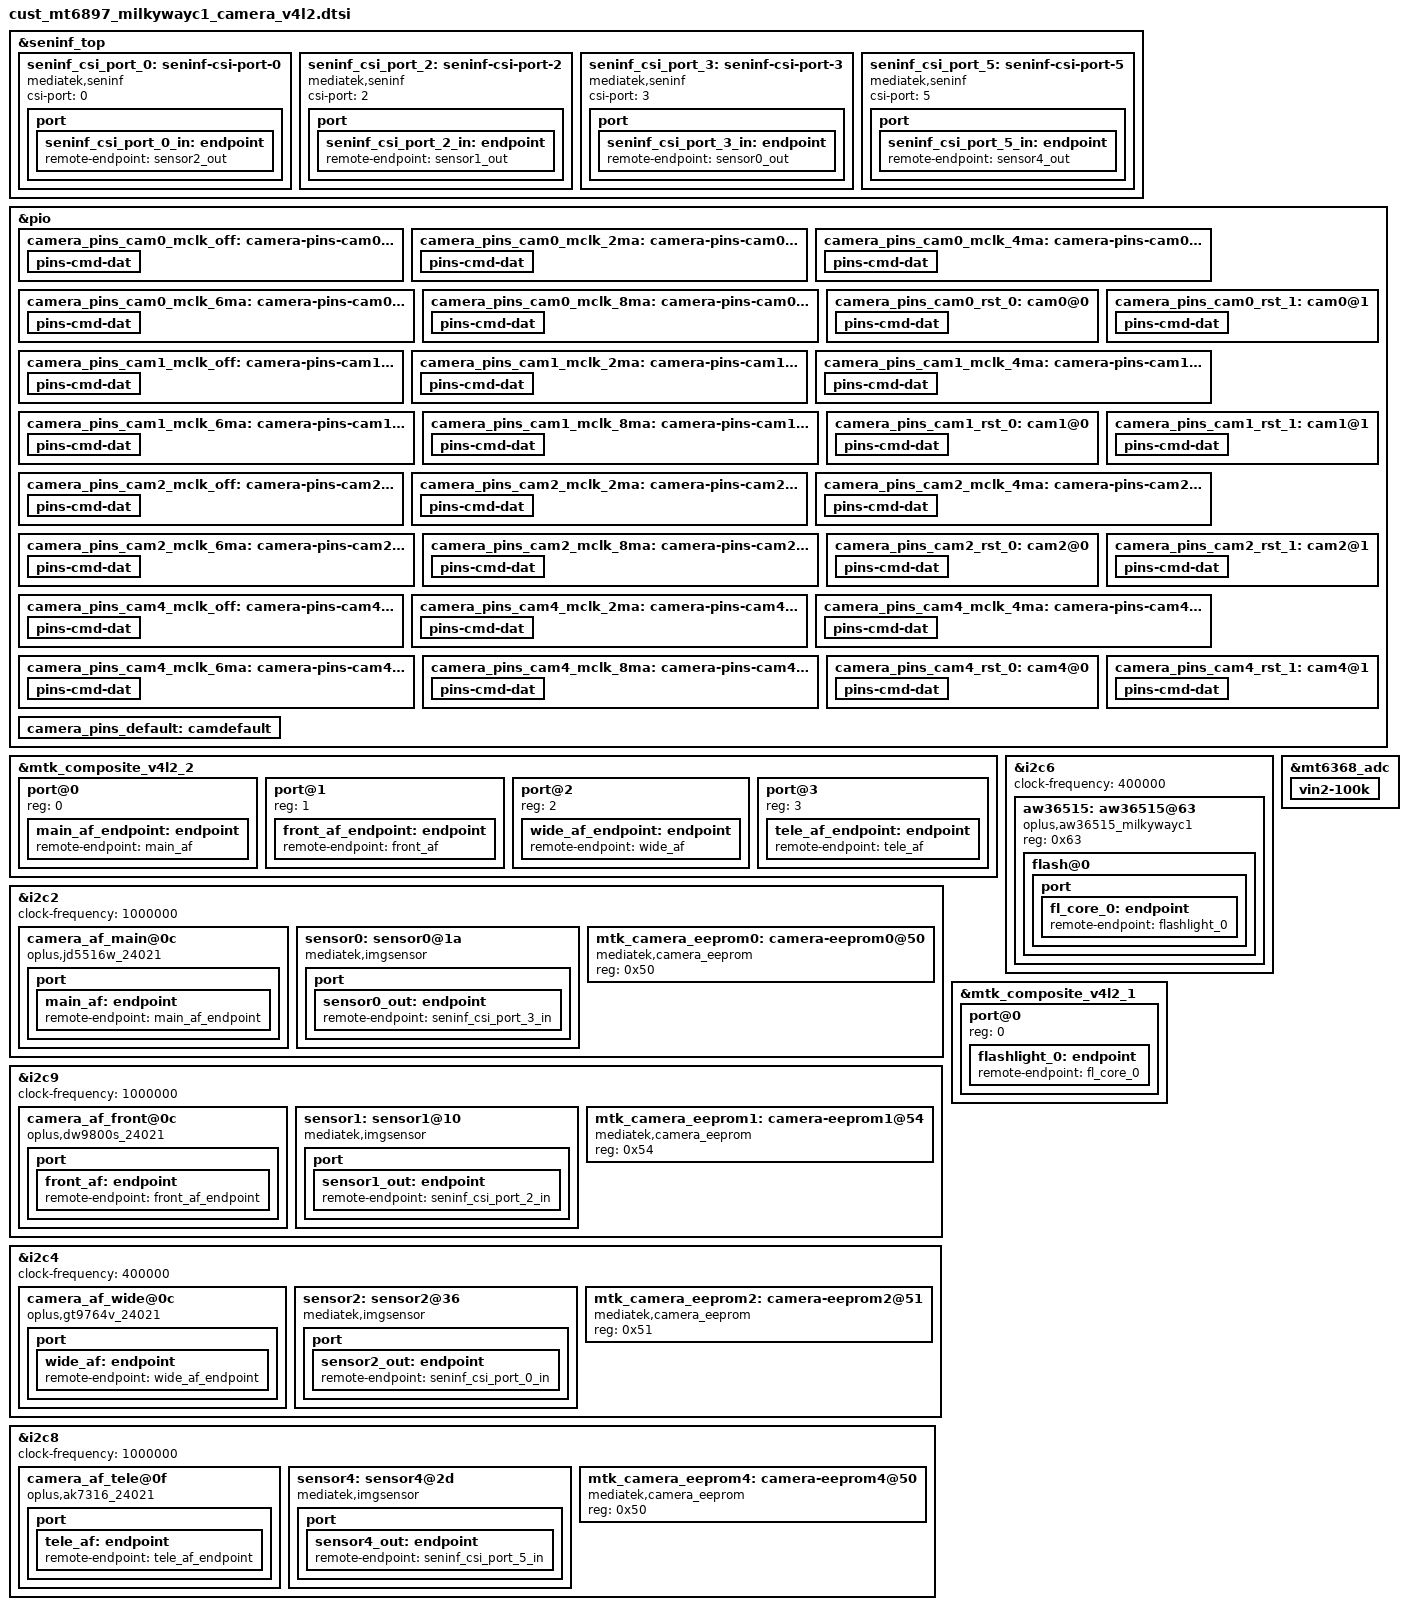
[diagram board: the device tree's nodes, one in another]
// SPDX-License-Identifier: GPL-2.0
/* Copyright (c) 2020 MediaTek Inc. */
#include <dt-bindings/clock/mt6897-clk.h>
#include "mediatek/milkywayc1_regulator_wl28681c.dtsi"
#include "../../../../../../vendor/oplus/kernel/camera/imgsensor/inc/oplus_kd_imgsensor.h"

&seninf_top {
		seninf_csi_port_0: seninf-csi-port-0 {
			compatible = "mediatek,seninf";
			csi-port = "0";

			port {
				seninf_csi_port_0_in: endpoint {
					remote-endpoint = <&sensor2_out>;
				};
			};
		};

		seninf_csi_port_2: seninf-csi-port-2 {
			compatible = "mediatek,seninf";
			csi-port = "2";

			port {
				seninf_csi_port_2_in: endpoint {
					remote-endpoint = <&sensor1_out>;
				};
			};
		};

		seninf_csi_port_3: seninf-csi-port-3 {
			compatible = "mediatek,seninf";
			csi-port = "3";

			port {
				seninf_csi_port_3_in: endpoint {
					remote-endpoint = <&sensor0_out>;
				};
			};
		};

		seninf_csi_port_5: seninf-csi-port-5 {
			compatible = "mediatek,seninf";
			csi-port = "5";

			port {
				seninf_csi_port_5_in: endpoint {
					remote-endpoint = <&sensor4_out>;
				};
			};
		};
};

/* CAMERA GPIO standardization */
&pio {
	camera_pins_cam0_mclk_off: camera-pins-cam0-mclk-off {
		pins-cmd-dat {
			pinmux = <PINMUX_GPIO123__FUNC_GPIO123>;
			drive-strength = <1>;
		};
	};
	camera_pins_cam0_mclk_2ma: camera-pins-cam0-mclk-2ma {
		pins-cmd-dat {
			pinmux = <PINMUX_GPIO123__FUNC_CMMCLK0>;
			drive-strength = <0>;
		};
	};
	camera_pins_cam0_mclk_4ma: camera-pins-cam0-mclk-4ma {
		pins-cmd-dat {
			pinmux = <PINMUX_GPIO123__FUNC_CMMCLK0>;
			drive-strength = <1>;
		};
	};
	camera_pins_cam0_mclk_6ma: camera-pins-cam0-mclk-6ma {
		pins-cmd-dat {
			pinmux = <PINMUX_GPIO123__FUNC_CMMCLK0>;
			drive-strength = <2>;
		};
	};
	camera_pins_cam0_mclk_8ma: camera-pins-cam0-mclk-8ma {
		pins-cmd-dat {
			pinmux = <PINMUX_GPIO123__FUNC_CMMCLK0>;
			drive-strength = <3>;
		};
	};
	camera_pins_cam0_rst_0: cam0@0 {
		pins-cmd-dat {
			pinmux = <PINMUX_GPIO115__FUNC_GPIO115>;
			slew-rate = <1>;
			output-low;
		};
	};
	camera_pins_cam0_rst_1: cam0@1 {
		pins-cmd-dat {
			pinmux = <PINMUX_GPIO115__FUNC_GPIO115>;
			slew-rate = <1>;
			output-high;
		};
	};

	camera_pins_cam1_mclk_off: camera-pins-cam1-mclk-off {
		pins-cmd-dat {
			pinmux = <PINMUX_GPIO126__FUNC_GPIO126>;
			drive-strength = <1>;
		};
	};
	camera_pins_cam1_mclk_2ma: camera-pins-cam1-mclk-2ma {
		pins-cmd-dat {
			pinmux = <PINMUX_GPIO126__FUNC_CMMCLK3>;
			drive-strength = <0>;
		};
	};
	camera_pins_cam1_mclk_4ma: camera-pins-cam1-mclk-4ma {
		pins-cmd-dat {
			pinmux = <PINMUX_GPIO126__FUNC_CMMCLK3>;
			drive-strength = <1>;
		};
	};
	camera_pins_cam1_mclk_6ma: camera-pins-cam1-mclk-6ma {
		pins-cmd-dat {
			pinmux = <PINMUX_GPIO126__FUNC_CMMCLK3>;
			drive-strength = <2>;
		};
	};
	camera_pins_cam1_mclk_8ma: camera-pins-cam1-mclk-8ma {
		pins-cmd-dat {
			pinmux = <PINMUX_GPIO126__FUNC_CMMCLK3>;
			drive-strength = <3>;
		};
	};
	camera_pins_cam1_rst_0: cam1@0 {
		pins-cmd-dat {
			pinmux = <PINMUX_GPIO118__FUNC_GPIO118>;
			slew-rate = <1>;
			output-low;
		};
	};
	camera_pins_cam1_rst_1: cam1@1 {
		pins-cmd-dat {
			pinmux = <PINMUX_GPIO118__FUNC_GPIO118>;
			slew-rate = <1>;
			output-high;
		};
	};

	camera_pins_cam2_mclk_off: camera-pins-cam2-mclk-off {
		pins-cmd-dat {
			pinmux = <PINMUX_GPIO124__FUNC_GPIO124>;
			drive-strength = <1>;
		};
	};
	camera_pins_cam2_mclk_2ma: camera-pins-cam2-mclk-2ma {
		pins-cmd-dat {
			pinmux = <PINMUX_GPIO124__FUNC_CMMCLK1>;
			drive-strength = <0>;
		};
	};
	camera_pins_cam2_mclk_4ma: camera-pins-cam2-mclk-4ma {
		pins-cmd-dat {
			pinmux = <PINMUX_GPIO124__FUNC_CMMCLK1>;
			drive-strength = <1>;
		};
	};
	camera_pins_cam2_mclk_6ma: camera-pins-cam2-mclk-6ma {
		pins-cmd-dat {
			pinmux = <PINMUX_GPIO124__FUNC_CMMCLK1>;
			drive-strength = <2>;
		};
	};
	camera_pins_cam2_mclk_8ma: camera-pins-cam2-mclk-8ma {
		pins-cmd-dat {
			pinmux = <PINMUX_GPIO124__FUNC_CMMCLK1>;
			drive-strength = <3>;
		};
	};
	camera_pins_cam2_rst_0: cam2@0 {
		pins-cmd-dat {
			pinmux = <PINMUX_GPIO116__FUNC_GPIO116>;
			slew-rate = <1>;
			output-low;
		};
	};
	camera_pins_cam2_rst_1: cam2@1 {
		pins-cmd-dat {
			pinmux = <PINMUX_GPIO116__FUNC_GPIO116>;
			slew-rate = <1>;
			output-high;
		};
	};

	camera_pins_cam4_mclk_off: camera-pins-cam4-mclk-off {
		pins-cmd-dat {
			pinmux = <PINMUX_GPIO125__FUNC_GPIO125>;
			drive-strength = <1>;
		};
	};
	camera_pins_cam4_mclk_2ma: camera-pins-cam4-mclk-2ma {
		pins-cmd-dat {
			pinmux = <PINMUX_GPIO125__FUNC_CMMCLK2>;
			drive-strength = <0>;
		};
	};
	camera_pins_cam4_mclk_4ma: camera-pins-cam4-mclk-4ma {
		pins-cmd-dat {
			pinmux = <PINMUX_GPIO125__FUNC_CMMCLK2>;
			drive-strength = <1>;
		};
	};
	camera_pins_cam4_mclk_6ma: camera-pins-cam4-mclk-6ma {
		pins-cmd-dat {
			pinmux = <PINMUX_GPIO125__FUNC_CMMCLK2>;
			drive-strength = <2>;
		};
	};
	camera_pins_cam4_mclk_8ma: camera-pins-cam4-mclk-8ma {
		pins-cmd-dat {
			pinmux = <PINMUX_GPIO125__FUNC_CMMCLK2>;
			drive-strength = <3>;
		};
	};
	camera_pins_cam4_rst_0: cam4@0 {
		pins-cmd-dat {
			pinmux = <PINMUX_GPIO117__FUNC_GPIO117>;
			slew-rate = <1>;
			output-low;
		};
	};
	camera_pins_cam4_rst_1: cam4@1 {
		pins-cmd-dat {
			pinmux = <PINMUX_GPIO117__FUNC_GPIO117>;
			slew-rate = <1>;
			output-high;
		};
	};
	camera_pins_default: camdefault {
	};
};
/* CAMERA GPIO end */

&mtk_composite_v4l2_2 {
	#address-cells = <1>;
	#size-cells = <0>;

	port@0 {
		reg = <0>;
		main_af_endpoint: endpoint {
			remote-endpoint = <&main_af>;
		};
	};
	port@1 {
		reg = <1>;
		front_af_endpoint: endpoint {
			remote-endpoint = <&front_af>;
		};
	};

	port@2 {
		reg = <2>;
		wide_af_endpoint: endpoint {
			remote-endpoint = <&wide_af>;
		};
	};

	port@3 {
		reg = <3>;
		tele_af_endpoint: endpoint {
			remote-endpoint = <&tele_af>;
		};
	};
};

&i2c2 {
	status = "okay";
	clock-frequency = <1000000>;

	camera_af_main@0c {
		compatible = "oplus,jd5516w_24021";
		reg = <0x0c>;
		vin-supply = <&wl28681c1_ldo4a>;
		port {
			main_af: endpoint {
				remote-endpoint = <&main_af_endpoint>;
			};
		};
	};

	sensor0: sensor0@1a {
		compatible = "mediatek,imgsensor";
		sensor-names = SENSOR_DRVNAME_MILKYWAYC1MAIN_MIPI_RAW;
		sensor-ids = <MILKYWAYC1MAIN_SENSOR_ID>;

		reg = <0x1a>;

		#thermal-sensor-cells = <0>;

		pinctrl-names = "mclk_off",
				"mclk_2mA",
				"mclk_4mA",
				"mclk_6mA",
				"mclk_8mA",
				"rst_low",
				"rst_high";
		pinctrl-0 = <&camera_pins_cam0_mclk_off>;
		pinctrl-1 = <&camera_pins_cam0_mclk_2ma>;
		pinctrl-2 = <&camera_pins_cam0_mclk_4ma>;
		pinctrl-3 = <&camera_pins_cam0_mclk_6ma>;
		pinctrl-4 = <&camera_pins_cam0_mclk_8ma>;
		pinctrl-5 = <&camera_pins_cam0_rst_0>;
		pinctrl-6 = <&camera_pins_cam0_rst_1>;

		avdd-supply = <&wl28681c1_ldo3a>;
		avdd1-supply = <&wl28681c1_ldo5a>;
		dvdd-supply = <&wl28681c1_ldo1a>;
		dovdd-supply = <&mt6368_vfp>;
		afvdd-supply = <&wl28681c1_ldo4a>;

		clocks = <&topckgen_clk CLK_TOP_UNIVPLL_192M_D32>,
			<&topckgen_clk CLK_TOP_UNIVPLL_192M_D16>,
			<&topckgen_clk CLK_TOP_F26M_CK_D2>,
			<&topckgen_clk CLK_TOP_UNIVPLL_192M_D10>,
			<&topckgen_clk CLK_TOP_UNIVPLL_192M_D8>,
			<&topckgen_clk CLK_TOP_UNIVPLL_D6_D16>,
			<&topckgen_clk CLK_TOP_UNIVPLL_D6_D8>,
			<&vlp_cksys_clk CLK_VLP_CK_CAMTG_SEL>;  //mclk0
		clock-names = "6", "12", "13", "19.2", "24", "26", "52", "mclk";

		status = "okay";
		port {
			sensor0_out: endpoint {
				remote-endpoint = <&seninf_csi_port_3_in>;
			};
		};
	};

	mtk_camera_eeprom0:camera-eeprom0@50 {
		compatible = "mediatek,camera_eeprom";
		reg = <0x50>;
		status = "okay";
	};
};

&i2c9 {
	status = "okay";
	clock-frequency = <1000000>;

	camera_af_front@0c {
		compatible = "oplus,dw9800s_24021";
		reg = <0x0c>;
		vin-supply = <&wl28681c1_ldo4a>;
		port {
			front_af: endpoint {
				remote-endpoint = <&front_af_endpoint>;
			};
		};
	};

	sensor1: sensor1@10 {
		compatible = "mediatek,imgsensor";
		sensor-names = SENSOR_DRVNAME_MILKYWAYC1FRONT_MIPI_RAW;
		sensor-ids = <MILKYWAYC1FRONT_SENSOR_ID>;

		reg = <0x10>;
		#reindex-to = <0>;
		#cust-aov-csi-clk = <312>;
		#thermal-sensor-cells = <0>;

		pinctrl-names = "mclk_off",
				"mclk_2mA",
				"mclk_4mA",
				"mclk_6mA",
				"mclk_8mA",
				"rst_low",
				"rst_high";

		pinctrl-0 = <&camera_pins_cam1_mclk_off>;
		pinctrl-1 = <&camera_pins_cam1_mclk_2ma>;
		pinctrl-2 = <&camera_pins_cam1_mclk_4ma>;
		pinctrl-3 = <&camera_pins_cam1_mclk_6ma>;
		pinctrl-4 = <&camera_pins_cam1_mclk_8ma>;
		pinctrl-5 = <&camera_pins_cam1_rst_0>;
		pinctrl-6 = <&camera_pins_cam1_rst_1>;

		avdd-supply = <&wl28681c1_ldo6a>;
		dvdd-supply = <&mt6319_7_vbuck4>;
		dvdd1-supply = <&wl28681c1_ldo2a>;
		dvdd-mode = <0x01>;   // REGULATOR_MODE_FAST
		dovdd-supply = <&mt6368_vfp>;
		afvdd-supply = <&wl28681c1_ldo4a>;

		clocks = <&topckgen_clk CLK_TOP_UNIVPLL_192M_D32>,
			<&topckgen_clk CLK_TOP_UNIVPLL_192M_D16>,
			<&topckgen_clk CLK_TOP_F26M_CK_D2>,
			<&topckgen_clk CLK_TOP_UNIVPLL_192M_D10>,
			<&topckgen_clk CLK_TOP_UNIVPLL_192M_D8>,
			<&topckgen_clk CLK_TOP_UNIVPLL_D6_D16>,
			<&topckgen_clk CLK_TOP_UNIVPLL_D6_D8>,
			<&topckgen_clk CLK_TOP_CAMTG4_SEL>;   //mclk3
		clock-names = "6", "12", "13", "19.2", "24", "26", "52", "mclk";

		status = "okay";
		port {
			sensor1_out: endpoint {
				remote-endpoint = <&seninf_csi_port_2_in>;
			};
		};
	};

    mtk_camera_eeprom1:camera-eeprom1@54 {
		compatible = "mediatek,camera_eeprom";
		reg = <0x54>;
		status = "okay";
	};
};

&i2c4 {
	status = "okay";
	clock-frequency = <400000>;

	camera_af_wide@0c {
		compatible = "oplus,gt9764v_24021";
		reg = <0x0c>;
		vin-supply = <&wl28681c1_ldo4a>;
		port {
			wide_af: endpoint {
				remote-endpoint = <&wide_af_endpoint>;
			};
		};
	};

   sensor2: sensor2@36 {
		compatible = "mediatek,imgsensor";
		sensor-names = SENSOR_DRVNAME_MILKYWAYC1WIDE_MIPI_RAW;
		sensor-ids = <MILKYWAYC1WIDE_SENSOR_ID>;

		reg = <0x36>;
		#reindex-to = <0>;
		#cust-aov-csi-clk = <312>;
		#thermal-sensor-cells = <0>;

		pinctrl-names = "mclk_off",
				"mclk_2mA",
				"mclk_4mA",
				"mclk_6mA",
				"mclk_8mA",
				"rst_low",
				"rst_high";

		pinctrl-0 = <&camera_pins_cam2_mclk_off>;
		pinctrl-1 = <&camera_pins_cam2_mclk_2ma>;
		pinctrl-2 = <&camera_pins_cam2_mclk_4ma>;
		pinctrl-3 = <&camera_pins_cam2_mclk_6ma>;
		pinctrl-4 = <&camera_pins_cam2_mclk_8ma>;
		pinctrl-5 = <&camera_pins_cam2_rst_0>;
		pinctrl-6 = <&camera_pins_cam2_rst_1>;

		avdd-supply = <&wl28681c1_ldo3a>;
		dvdd-supply = <&mt6368_vrf13_aif>;
		dovdd-supply = <&mt6368_vfp>;
		afvdd-supply = <&wl28681c1_ldo4a>;

		clocks = <&topckgen_clk CLK_TOP_UNIVPLL_192M_D32>,
			<&topckgen_clk CLK_TOP_UNIVPLL_192M_D16>,
			<&topckgen_clk CLK_TOP_F26M_CK_D2>,
			<&topckgen_clk CLK_TOP_UNIVPLL_192M_D10>,
			<&topckgen_clk CLK_TOP_UNIVPLL_192M_D8>,
			<&topckgen_clk CLK_TOP_UNIVPLL_D6_D16>,
			<&topckgen_clk CLK_TOP_UNIVPLL_D6_D8>,
			<&topckgen_clk CLK_TOP_CAMTG2_SEL>;  //mclk1
		clock-names = "6", "12", "13", "19.2", "24", "26", "52", "mclk";

		status = "okay";
		port {
			sensor2_out: endpoint {
				remote-endpoint = <&seninf_csi_port_0_in>;
			};
		};
	};

	mtk_camera_eeprom2:camera-eeprom2@51 {
		compatible = "mediatek,camera_eeprom";
		reg = <0x51>;
		status = "okay";
	};
};

&i2c8 {
	status = "okay";
	clock-frequency = <1000000>;

	camera_af_tele@0f {
		compatible = "oplus,ak7316_24021";
		reg = <0x0f>;
		vin-supply = <&wl28681c1_ldo7a>;
		port {
			tele_af: endpoint {
				remote-endpoint = <&tele_af_endpoint>;
			};
		};
	};

	sensor4: sensor4@2d {
		compatible = "mediatek,imgsensor";
		sensor-names = SENSOR_DRVNAME_MILKYWAYC1TELE_MIPI_RAW;
		sensor-ids = <MILKYWAYC1TELE_SENSOR_ID>;
		reg = <0x2d>;

		#thermal-sensor-cells = <0>;

		pinctrl-names = "mclk_off",
				"mclk_2mA",
				"mclk_4mA",
				"mclk_6mA",
				"mclk_8mA",
				"rst_low",
				"rst_high";
		pinctrl-0 = <&camera_pins_cam4_mclk_off>;
		pinctrl-1 = <&camera_pins_cam4_mclk_2ma>;
		pinctrl-2 = <&camera_pins_cam4_mclk_4ma>;
		pinctrl-3 = <&camera_pins_cam4_mclk_6ma>;
		pinctrl-4 = <&camera_pins_cam4_mclk_8ma>;
		pinctrl-5 = <&camera_pins_cam4_rst_0>;
		pinctrl-6 = <&camera_pins_cam4_rst_1>;

		avdd-supply = <&wl28681c1_ldo6a>;
		dvdd-supply = <&wl28681c1_ldo2a>;
		dovdd-supply = <&mt6368_vfp>;
		afvdd-supply = <&wl28681c1_ldo7a>;

		clocks = <&topckgen_clk CLK_TOP_UNIVPLL_192M_D32>,
			<&topckgen_clk CLK_TOP_UNIVPLL_192M_D16>,
			<&topckgen_clk CLK_TOP_F26M_CK_D2>,
			<&topckgen_clk CLK_TOP_UNIVPLL_192M_D10>,
			<&topckgen_clk CLK_TOP_UNIVPLL_192M_D8>,
			<&topckgen_clk CLK_TOP_UNIVPLL_D6_D16>,
			<&topckgen_clk CLK_TOP_UNIVPLL_D6_D8>,
			<&topckgen_clk CLK_TOP_CAMTG3_SEL>;  //mclk2
		clock-names = "6", "12", "13", "19.2", "24", "26", "52", "mclk";

		status = "okay";
		port {
			sensor4_out: endpoint {
				remote-endpoint = <&seninf_csi_port_5_in>;
			};
		};
	};

	mtk_camera_eeprom4:camera-eeprom4@50 {
		compatible = "mediatek,camera_eeprom";
		reg = <0x50>;
		status = "okay";
	};
};

//flashlight
//&pio {
//	aw36515_pins_default: default {
//	};
//
//	aw36515_pins_hwen_high: hwen-high {
//		pins_cmd_dat {
//			pinmux = <PINMUX_GPIO153__FUNC_GPIO153>;// nobody use,just test
//			slew-rate = <1>;
//			output-high;
//		};
//	};
//
//	aw36515_pins_hwen_low: hwen-low {
//		pins_cmd_dat {
//			pinmux = <PINMUX_GPIO153__FUNC_GPIO153>;
//			slew-rate = <1>;
//			output-low;
//		};
//	};
//};

&i2c6 {
	clock-frequency = <400000>;
	#address-cells = <1>;
	#size-cells = <0>;
	aw36515:aw36515@63 {
		compatible = "oplus,aw36515_milkywayc1";
		#address-cells = <1>;
		#size-cells = <0>;
		reg = <0x63>;
		#cooling-cells = <2>;
//		pinctrl-names = "default", "hwen-high", "hwen-low";
//		pinctrl-0 = <&aw36515_pins_default>;
//		pinctrl-1 = <&aw36515_pins_hwen_high>;
//		pinctrl-2 = <&aw36515_pins_hwen_low>;
		status = "okay";
		flash@0{
			reg = <0>;
			type = <0>;
			ct = <0>;
			part = <0>;
			port {
				fl_core_0: endpoint {
					remote-endpoint = <&flashlight_0>;
				};
			};
		};
	};
};

&mtk_composite_v4l2_1 {
	#address-cells = <1>;
	#size-cells = <0>;
	port@0 {
		reg = <0>;
		flashlight_0: endpoint {
			remote-endpoint = <&fl_core_0>;
		};
	};
};


&mt6368_adc {
	vin2-100k {
		channel = <AUXADC_VIN2>;
		pures = <ADC_PURES_100K>;
	};
};
